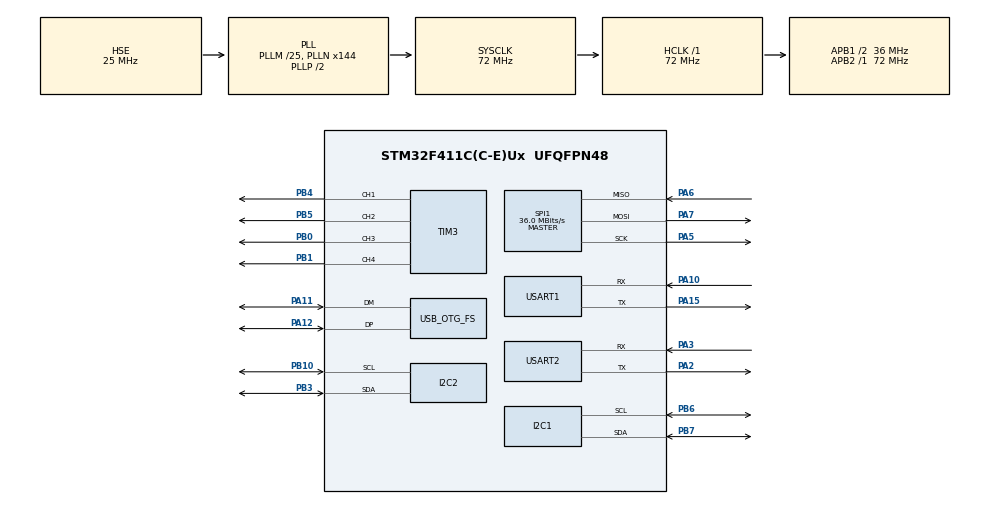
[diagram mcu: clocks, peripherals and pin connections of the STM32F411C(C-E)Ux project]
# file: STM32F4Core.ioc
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FREERTOS.Mutexes01=RevcMutex,Dynamic,NULL;SendMutex,Dynamic,NULL
FREERTOS.Queues01=MainQueue,16,uint16_t,0,Dynamic,NULL,NULL
FREERTOS.Tasks01=defaultTask,0,128,StartDefaultTask,Default,NULL,Dynamic,NULL,NULL;mainTask,-3,128,StartmainTask,Default,NULL,Dynamic,NULL,NULL;UpdateTask,-3,128,StartUpdateTask,Default,NULL,Dynamic,NULL,NULL;AngleTask,-3,128,StartAngleTask,Default,NULL,Dynamic,NULL,NULL
FREERTOS.configUSE_NEWLIB_REENTRANT=1
Mcu.Family=STM32F4
Mcu.Name=STM32F411C(C-E)Ux
Mcu.Package=UFQFPN48
NVIC.OTG_FS_IRQn=true\:5\:0\:false\:false\:true\:true\:false\:true\:true
NVIC.PriorityGroup=NVIC_PRIORITYGROUP_4
NVIC.TIM1_UP_TIM10_IRQn=true\:15\:0\:false\:false\:true\:false\:false\:true\:true
NVIC.TimeBase=TIM1_UP_TIM10_IRQn
NVIC.TimeBaseIP=TIM1
PA10.Mode=Asynchronous
PA10.Signal=USART1_RX
PA11.Mode=Device_Only
PA11.Signal=USB_OTG_FS_DM
PA12.Mode=Device_Only
PA12.Signal=USB_OTG_FS_DP
PA13.Mode=Serial_Wire
PA13.Signal=SYS_JTMS-SWDIO
PA14.Mode=Serial_Wire
PA14.Signal=SYS_JTCK-SWCLK
PA15.Mode=Asynchronous
PA15.Signal=USART1_TX
PA2.Mode=Asynchronous
PA2.Signal=USART2_TX
PA3.Mode=Asynchronous
PA3.Signal=USART2_RX
PA5.Mode=Full_Duplex_Master
PA5.Signal=SPI1_SCK
PA6.Mode=Full_Duplex_Master
PA6.Signal=SPI1_MISO
PA7.Mode=Full_Duplex_Master
PA7.Signal=SPI1_MOSI
PB0.Signal=S_TIM3_CH3
PB1.Signal=S_TIM3_CH4
PB10.Mode=I2C
PB10.Signal=I2C2_SCL
PB3.Mode=I2C
PB3.Signal=I2C2_SDA
PB4.Signal=S_TIM3_CH1
PB5.Signal=S_TIM3_CH2
PB6.Mode=I2C
PB6.Signal=I2C1_SCL
PB7.Mode=I2C
PB7.Signal=I2C1_SDA
PH0\ -\ OSC_IN.Mode=HSE-External-Oscillator
PH0\ -\ OSC_IN.Signal=RCC_OSC_IN
PH1\ -\ OSC_OUT.Mode=HSE-External-Oscillator
PH1\ -\ OSC_OUT.Signal=RCC_OSC_OUT
ProjectManager.HeapSize=0x200
ProjectManager.StackSize=0x400
ProjectManager.TargetToolchain=STM32CubeIDE
RCC.48MHZClocksFreq_Value=48000000
RCC.AHBFreq_Value=72000000
RCC.APB1CLKDivider=RCC_HCLK_DIV2
RCC.APB1Freq_Value=36000000
RCC.APB1TimFreq_Value=72000000
RCC.APB2Freq_Value=72000000
RCC.APB2TimFreq_Value=72000000
RCC.CortexFreq_Value=72000000
RCC.HCLKFreq_Value=72000000
RCC.HSE_VALUE=25000000
RCC.HSI_VALUE=16000000
RCC.LSE_VALUE=32768
RCC.PLLM=25
RCC.PLLN=144
RCC.PLLQ=3
RCC.SYSCLKFreq_VALUE=72000000
RCC.SYSCLKSource=RCC_SYSCLKSOURCE_PLLCLK
RCC.VCOOutputFreq_Value=144000000
SH.S_TIM3_CH1.0=TIM3_CH1,PWM Generation1 CH1
SH.S_TIM3_CH2.0=TIM3_CH2,PWM Generation2 CH2
SH.S_TIM3_CH3.0=TIM3_CH3,PWM Generation3 CH3
SH.S_TIM3_CH4.0=TIM3_CH4,PWM Generation4 CH4
SPI1.CalculateBaudRate=36.0 MBits/s
SPI1.Direction=SPI_DIRECTION_2LINES
SPI1.Mode=SPI_MODE_MASTER
SPI1.VirtualType=VM_MASTER
TIM3.Channel-PWM\ Generation1\ CH1=TIM_CHANNEL_1
TIM3.Channel-PWM\ Generation2\ CH2=TIM_CHANNEL_2
TIM3.Channel-PWM\ Generation3\ CH3=TIM_CHANNEL_3
TIM3.Channel-PWM\ Generation4\ CH4=TIM_CHANNEL_4
USART1.VirtualMode=VM_ASYNC
USART2.VirtualMode=VM_ASYNC
USB_DEVICE.CLASS_NAME_FS=HID
USB_DEVICE.VirtualMode=Hid
USB_DEVICE.VirtualModeFS=Hid_FS
USB_OTG_FS.VirtualMode=Device_Only
VP_FREERTOS_VS_CMSIS_V1.Mode=CMSIS_V1
VP_SYS_VS_tim1.Mode=TIM1
VP_USB_DEVICE_VS_USB_DEVICE_HID_FS.Mode=HID_FS
board=custom

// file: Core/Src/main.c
/* USER CODE BEGIN Header */
/**
  ******************************************************************************
  * @file           : main.c
  * @brief          : Main program body
  ******************************************************************************
  * @attention
  *
  * Copyright (c) 2023 STMicroelectronics.
  * All rights reserved.
  *
  * This software is licensed under terms that can be found in the LICENSE file
  * in the root directory of this software component.
  * If no LICENSE file comes with this software, it is provided AS-IS.
  *
  ******************************************************************************
  */
/* USER CODE END Header */
#include "main.h"
#include "cmsis_os.h"
#include "i2c.h"
#include "spi.h"
#include "tim.h"
#include "usart.h"
#include "usb_device.h"
#include "gpio.h"

void SystemClock_Config(void);
void MX_FREERTOS_Init(void);

int main(void)
{

  /* MCU Configuration--------------------------------------------------------*/

  /* Reset of all peripherals, Initializes the Flash interface and the Systick. */
  HAL_Init();

  /* Configure the system clock */
  SystemClock_Config();

  /* Initialize all configured peripherals */
  MX_GPIO_Init();
  MX_I2C1_Init();
  MX_USART1_UART_Init();
  MX_I2C2_Init();
  MX_SPI1_Init();
  MX_USART2_UART_Init();
  MX_TIM3_Init();

  /* Call init function for freertos objects (in freertos.c) */
  MX_FREERTOS_Init();

  /* Start scheduler */
  osKernelStart();
  /* We should never get here as control is now taken by the scheduler */
  /* Infinite loop */
  while (1)
  {

  }
}

void SystemClock_Config(void)
{
  RCC_OscInitTypeDef RCC_OscInitStruct = {0};
  RCC_ClkInitTypeDef RCC_ClkInitStruct = {0};

  /** Configure the main internal regulator output voltage
  */
  __HAL_RCC_PWR_CLK_ENABLE();
  __HAL_PWR_VOLTAGESCALING_CONFIG(PWR_REGULATOR_VOLTAGE_SCALE1);

  /** Initializes the RCC Oscillators according to the specified parameters
  * in the RCC_OscInitTypeDef structure.
  */
  RCC_OscInitStruct.OscillatorType = RCC_OSCILLATORTYPE_HSE;
  RCC_OscInitStruct.HSEState = RCC_HSE_ON;
  RCC_OscInitStruct.PLL.PLLState = RCC_PLL_ON;
  RCC_OscInitStruct.PLL.PLLSource = RCC_PLLSOURCE_HSE;
  RCC_OscInitStruct.PLL.PLLM = 25;
  RCC_OscInitStruct.PLL.PLLN = 144;
  RCC_OscInitStruct.PLL.PLLP = RCC_PLLP_DIV2;
  RCC_OscInitStruct.PLL.PLLQ = 3;
  if (HAL_RCC_OscConfig(&RCC_OscInitStruct) != HAL_OK)
  {
    Error_Handler();
  }

  /** Initializes the CPU, AHB and APB buses clocks
  */
  RCC_ClkInitStruct.ClockType = RCC_CLOCKTYPE_HCLK|RCC_CLOCKTYPE_SYSCLK
                              |RCC_CLOCKTYPE_PCLK1|RCC_CLOCKTYPE_PCLK2;
  RCC_ClkInitStruct.SYSCLKSource = RCC_SYSCLKSOURCE_PLLCLK;
  RCC_ClkInitStruct.AHBCLKDivider = RCC_SYSCLK_DIV1;
  RCC_ClkInitStruct.APB1CLKDivider = RCC_HCLK_DIV2;
  RCC_ClkInitStruct.APB2CLKDivider = RCC_HCLK_DIV1;

  if (HAL_RCC_ClockConfig(&RCC_ClkInitStruct, FLASH_LATENCY_2) != HAL_OK)
  {
    Error_Handler();
  }
}

void HAL_TIM_PeriodElapsedCallback(TIM_HandleTypeDef *htim)
{
  if (htim->Instance == TIM1) {
    HAL_IncTick();
  }
}

void Error_Handler(void)
{
  __disable_irq();
  while (1)
  {
  }
}

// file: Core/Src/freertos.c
/* USER CODE BEGIN Header */
/**
  ******************************************************************************
  * File Name          : freertos.c
  * Description        : Code for freertos applications
  ******************************************************************************
  * @attention
  *
  * Copyright (c) 2023 STMicroelectronics.
  * All rights reserved.
  *
  * This software is licensed under terms that can be found in the LICENSE file
  * in the root directory of this software component.
  * If no LICENSE file comes with this software, it is provided AS-IS.
  *
  ******************************************************************************
  */
/* USER CODE END Header */

#include "FreeRTOS.h"
#include "task.h"
#include "main.h"
#include "cmsis_os.h"

/* USER CODE BEGIN Includes */
#include "app.h"

/* USER CODE END Includes */

osThreadId defaultTaskHandle;
osThreadId mainTaskHandle;
osThreadId UpdateTaskHandle;
osThreadId AngleTaskHandle;
osMessageQId MainQueueHandle;
osMutexId RevcMutexHandle;
osMutexId SendMutexHandle;

void StartDefaultTask(void const * argument);
void StartmainTask(void const * argument);
void StartUpdateTask(void const * argument);
void StartAngleTask(void const * argument);

extern void MX_USB_DEVICE_Init(void);
void MX_FREERTOS_Init(void); /* (MISRA C 2004 rule 8.1) */

/* GetIdleTaskMemory prototype (linked to static allocation support) */
void vApplicationGetIdleTaskMemory( StaticTask_t **ppxIdleTaskTCBBuffer, StackType_t **ppxIdleTaskStackBuffer, uint32_t *pulIdleTaskStackSize );

/* USER CODE BEGIN GET_IDLE_TASK_MEMORY */
static StaticTask_t xIdleTaskTCBBuffer;
static StackType_t xIdleStack[configMINIMAL_STACK_SIZE];

void vApplicationGetIdleTaskMemory( StaticTask_t **ppxIdleTaskTCBBuffer, StackType_t **ppxIdleTaskStackBuffer, uint32_t *pulIdleTaskStackSize )
{
  *ppxIdleTaskTCBBuffer = &xIdleTaskTCBBuffer;
  *ppxIdleTaskStackBuffer = &xIdleStack[0];
  *pulIdleTaskStackSize = configMINIMAL_STACK_SIZE;
  /* place for user code */
}
/* USER CODE END GET_IDLE_TASK_MEMORY */

void MX_FREERTOS_Init(void) {
  /* USER CODE BEGIN Init */
	app_init();
  /* USER CODE END Init */
  /* Create the mutex(es) */
  /* definition and creation of RevcMutex */
  osMutexDef(RevcMutex);
  RevcMutexHandle = osMutexCreate(osMutex(RevcMutex));

  /* definition and creation of SendMutex */
  osMutexDef(SendMutex);
  SendMutexHandle = osMutexCreate(osMutex(SendMutex));

  /* Create the queue(s) */
  /* definition and creation of MainQueue */
  osMessageQDef(MainQueue, 16, uint16_t);
  MainQueueHandle = osMessageCreate(osMessageQ(MainQueue), NULL);

  /* Create the thread(s) */
  /* definition and creation of defaultTask */
  osThreadDef(defaultTask, StartDefaultTask, osPriorityNormal, 0, 128);
  defaultTaskHandle = osThreadCreate(osThread(defaultTask), NULL);

  /* definition and creation of mainTask */
  osThreadDef(mainTask, StartmainTask, osPriorityIdle, 0, 128);
  mainTaskHandle = osThreadCreate(osThread(mainTask), NULL);

  /* definition and creation of UpdateTask */
  osThreadDef(UpdateTask, StartUpdateTask, osPriorityIdle, 0, 128);
  UpdateTaskHandle = osThreadCreate(osThread(UpdateTask), NULL);

  /* definition and creation of AngleTask */
  osThreadDef(AngleTask, StartAngleTask, osPriorityIdle, 0, 128);
  AngleTaskHandle = osThreadCreate(osThread(AngleTask), NULL);

}

void StartDefaultTask(void const * argument)
{
  /* init code for USB_DEVICE */
  MX_USB_DEVICE_Init();
  for(;;)
  {
    osDelay(1);
  }
}

void StartmainTask(void const * argument)
{
  /* USER CODE BEGIN StartmainTask */
  /* Infinite loop */
  for(;;)
  {
	app_main();
    osDelay(2);
  }
  /* USER CODE END StartmainTask */
}

void StartUpdateTask(void const * argument)
{
  /* USER CODE BEGIN StartUpdateTask */
  /* Infinite loop */
  for(;;)
  {
    osDelay(3);
    app_update();
  }
  /* USER CODE END StartUpdateTask */
}

void StartAngleTask(void const * argument)
{
  /* USER CODE BEGIN StartAngleTask */
  /* Infinite loop */
  for(;;)
  {
    osDelay(6);
    app_calangle();
  }
  /* USER CODE END StartAngleTask */
}
